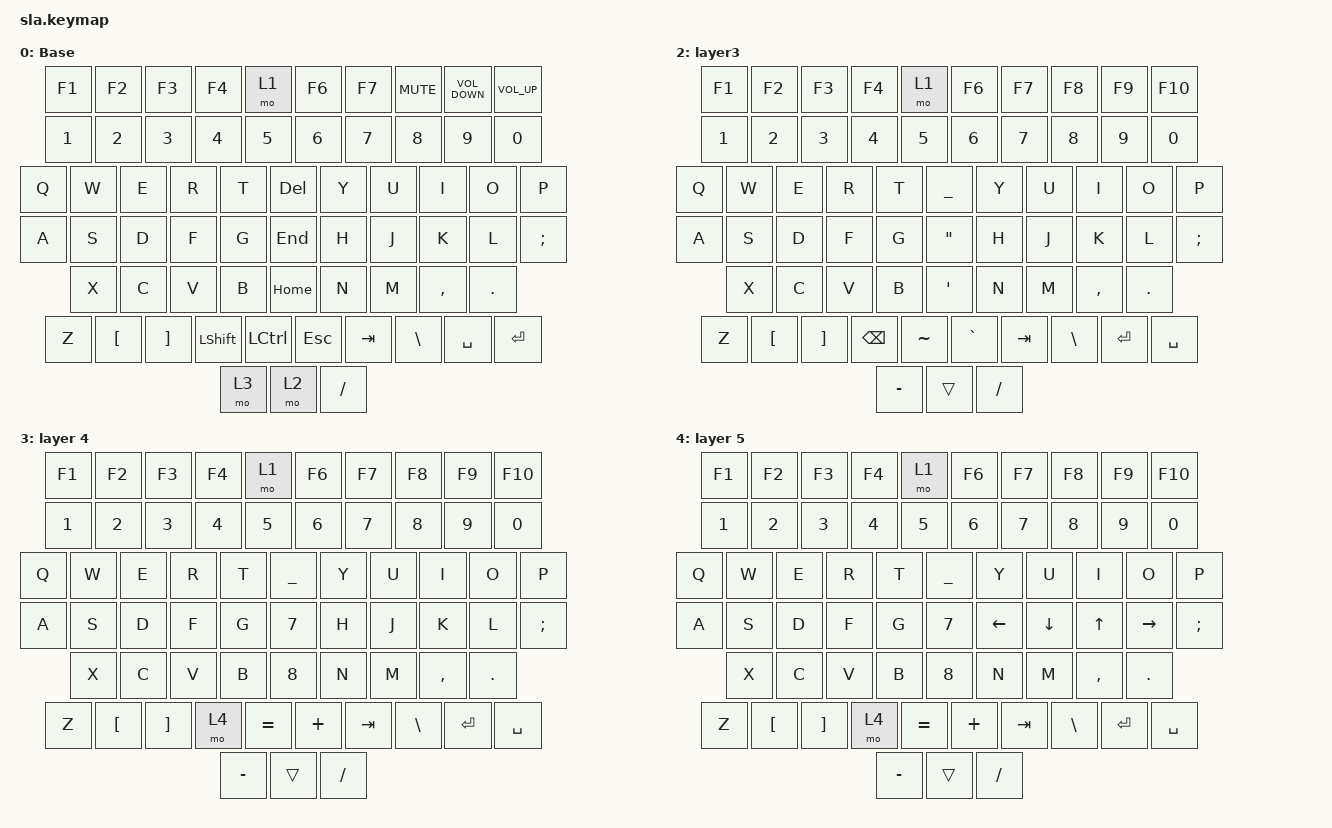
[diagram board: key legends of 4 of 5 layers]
//#include <behaviors.dtsi>
#include <dt-bindings/zmk/keys.h>
#include <behaviors.dtsi>
#include <dt-bindings/zmk/bt.h>

/ {
    keymap {
      compatible = "zmk,keymap";
      layout = <&default_layout>;

      default_layer {
        display-name = "Base";
        bindings = <
          &kp F1 &kp F2 &kp F3 &kp F4 &mo 1                       &kp F6 &kp F7 &kp C_MUTE &kp C_VOLUME_DOWN &kp C_VOLUME_UP
          &kp N1 &kp N2 &kp N3 &kp N4 &kp N5                      &kp N6 &kp N7 &kp N8 &kp N9 &kp N0
          &kp Q &kp W &kp E &kp R &kp T &kp DEL                   &kp Y &kp U &kp I &kp O &kp P
          &kp A &kp S &kp D &kp F &kp G &kp END                   &kp H &kp J &kp K &kp L &kp SEMI 
                &kp X &kp C &kp V &kp B &kp HOME                  &kp N &kp M &kp COMMA &kp PERIOD
          &kp Z &kp LBKT &kp RBKT &kp LSHIFT &kp LCTRL &kp ESC      &kp TAB &kp BSLH &kp SPACE &kp RET 
                                                                                &mo 3 &mo 2  &kp SLASH 
        >;


      };

      bt_layer {
        display-name = "layer 2";
        bindings = <
          &bt BT_CLR &bt BT_SEL 1 &bt BT_SEL 2 &bt BT_SEL 3 &trans          &studio_unlock 
        >;
      };
      
      anotha_layer { 
        display-name = "layer3";
        bindings = <
          &kp F1 &kp F2 &kp F3 &kp F4 &mo 1                       &kp F6 &kp F7 &kp F8 &kp F9 &kp F10
          &kp N1 &kp N2 &kp N3 &kp N4 &kp N5                      &kp N6 &kp N7 &kp N8 &kp N9 &kp N0
          &kp Q &kp W &kp E &kp R &kp T &kp UNDER                 &kp Y &kp U &kp I &kp O &kp P
          &kp A &kp S &kp D &kp F &kp G &kp DQT                   &kp H &kp J &kp K &kp L &kp SEMI 
                &kp X &kp C &kp V &kp B &kp SQT                   &kp N &kp M &kp COMMA &kp PERIOD
          &kp Z &kp LBKT &kp RBKT &kp BSPC &kp TILDE &kp GRAVE      &kp TAB &kp BSLH &kp RET &kp SPACE 
                                                                                &kp MINUS &trans  &kp SLASH
        >;
      }; 

      remaining_keys {
        display-name = "layer 4";
        bindings = <
          &kp F1 &kp F2 &kp F3 &kp F4 &mo 1                       &kp F6 &kp F7 &kp F8 &kp F9 &kp F10
          &kp N1 &kp N2 &kp N3 &kp N4 &kp N5                      &kp N6 &kp N7 &kp N8 &kp N9 &kp N0
          &kp Q &kp W &kp E &kp R &kp T &kp UNDER                 &kp Y &kp U &kp I &kp O &kp P
          &kp A &kp S &kp D &kp F &kp G &kp N7                   &kp H &kp J &kp K &kp L &kp SEMI 
                &kp X &kp C &kp V &kp B &kp  N8                  &kp N &kp M &kp COMMA &kp PERIOD
          &kp Z &kp LBKT &kp RBKT &mo 4 &kp EQUAL &kp PLUS      &kp TAB &kp BSLH &kp RET &kp SPACE 
                                                                                &kp MINUS &trans  &kp SLASH 
        >;

      };

      bla_layer {
        display-name = "layer 5";
        bindings = <
          &kp F1 &kp F2 &kp F3 &kp F4 &mo 1                       &kp F6 &kp F7 &kp F8 &kp F9 &kp F10
          &kp N1 &kp N2 &kp N3 &kp N4 &kp N5                      &kp N6 &kp N7 &kp N8 &kp N9 &kp N0
          &kp Q &kp W &kp E &kp R &kp T &kp UNDER                 &kp Y &kp U &kp I &kp O &kp P
          &kp A &kp S &kp D &kp F &kp G &kp N7                   &kp LEFT_ARROW &kp DOWN_ARROW &kp UP_ARROW &kp RIGHT_ARROW &kp SEMI 
                &kp X &kp C &kp V &kp B &kp  N8                  &kp N &kp M &kp COMMA &kp PERIOD
          &kp Z &kp LBKT &kp RBKT &mo 4 &kp EQUAL &kp PLUS      &kp TAB &kp BSLH &kp RET &kp SPACE 
                                                                                &kp MINUS &trans  &kp SLASH 
        >;
         
 
      };

    };
};
